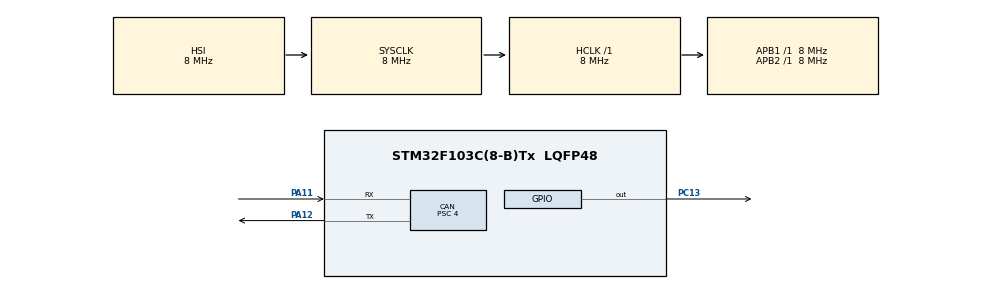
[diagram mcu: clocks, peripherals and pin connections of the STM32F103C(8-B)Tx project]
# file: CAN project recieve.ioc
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CAN.BS1=CAN_BS1_13TQ
CAN.BS2=CAN_BS2_2TQ
CAN.CalculateBaudRate=125000
CAN.CalculateTimeBit=8000
CAN.CalculateTimeQuantum=500.0
CAN.Prescaler=4
CAN.SJW=CAN_SJW_1TQ
Mcu.Family=STM32F1
Mcu.Name=STM32F103C(8-B)Tx
Mcu.Package=LQFP48
NVIC.PriorityGroup=NVIC_PRIORITYGROUP_4
NVIC.USB_LP_CAN1_RX0_IRQn=true\:0\:0\:false\:false\:true\:true\:true\:true
PA11.Mode=CAN_Activate
PA11.Signal=CAN_RX
PA12.Mode=CAN_Activate
PA12.Signal=CAN_TX
PC13-TAMPER-RTC.Signal=GPIO_Output
ProjectManager.HeapSize=0x200
ProjectManager.StackSize=0x400
ProjectManager.TargetToolchain=STM32CubeIDE
RCC.AHBFreq_Value=8000000
RCC.APB1Freq_Value=8000000
RCC.APB1TimFreq_Value=8000000
RCC.APB2Freq_Value=8000000
RCC.APB2TimFreq_Value=8000000
RCC.HCLKFreq_Value=8000000
RCC.SYSCLKFreq_VALUE=8000000
RCC.USBFreq_Value=8000000
VP_SYS_VS_ND.Mode=No_Debug
board=custom

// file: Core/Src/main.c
/* USER CODE BEGIN Header */
/**
  ******************************************************************************
  * @file           : main.c  (RECEIVER)
  * @brief          : Receives CAN frame ID 0x103, toggles LED on each frame
  ******************************************************************************
  */
/* USER CODE END Header */
#include "main.h"

CAN_HandleTypeDef hcan;

/* USER CODE BEGIN PV */
CAN_RxHeaderTypeDef   RxHeader;
uint8_t               RxData[3];
volatile uint8_t      datacheck = 0;
/* USER CODE END PV */

void SystemClock_Config(void);
static void MX_GPIO_Init(void);
static void MX_CAN_Init(void);

int main(void)
{

  /* MCU Configuration--------------------------------------------------------*/

  /* Reset of all peripherals, Initializes the Flash interface and the Systick. */
  HAL_Init();

  /* Configure the system clock */
  SystemClock_Config();

  /* Initialize all configured peripherals */
  MX_GPIO_Init();
  MX_CAN_Init();
  /* USER CODE BEGIN 2 */

  uint16_t acceptID = 0x002;
  /* At least one filter is required to receive. This one accepts all IDs. */
  CAN_FilterTypeDef canfilterconfig;
  canfilterconfig.FilterActivation     = CAN_FILTER_ENABLE;
  canfilterconfig.FilterBank           = 0;
  canfilterconfig.FilterFIFOAssignment = CAN_RX_FIFO0;
  canfilterconfig.FilterIdHigh         = acceptID << 5;		//the id that wil be accepted;
  canfilterconfig.FilterIdLow          = 0x0000;
  canfilterconfig.FilterMaskIdHigh     = 0x7FF << 5;		//compare the 11 bits;
  canfilterconfig.FilterMaskIdLow      = 0x0006;
  canfilterconfig.FilterMode           = CAN_FILTERMODE_IDMASK;
  canfilterconfig.FilterScale          = CAN_FILTERSCALE_32BIT;
  canfilterconfig.SlaveStartFilterBank = 14;

  if (HAL_CAN_ConfigFilter(&hcan, &canfilterconfig) != HAL_OK)
  {
    Error_Handler();
  }

  if (HAL_CAN_Start(&hcan) != HAL_OK)
  {
    Error_Handler();
  }

  /* Enables the interrupt inside the CAN peripheral.
     The NVIC line "CAN1 RX0 interrupt" must ALSO be enabled in CubeMX
     (CAN -> NVIC Settings) so CAN1_RX0_IRQHandler exists and calls HAL_CAN_IRQHandler. */
  if (HAL_CAN_ActivateNotification(&hcan, CAN_IT_RX_FIFO0_MSG_PENDING) != HAL_OK)
  {
    Error_Handler();
  }

  /* USER CODE END 2 */

  /* Infinite loop */
  /* USER CODE BEGIN WHILE */
  while (1)
  {
    if (datacheck)
    {
      datacheck = 0;
      HAL_GPIO_TogglePin(GPIOC, GPIO_PIN_13);
    }
    /* USER CODE END WHILE */

  }
}

void SystemClock_Config(void)
{
  RCC_OscInitTypeDef RCC_OscInitStruct = {0};
  RCC_ClkInitTypeDef RCC_ClkInitStruct = {0};

  /** Initializes the RCC Oscillators according to the specified parameters
  * in the RCC_OscInitTypeDef structure.
  */
  RCC_OscInitStruct.OscillatorType = RCC_OSCILLATORTYPE_HSI;
  RCC_OscInitStruct.HSIState = RCC_HSI_ON;
  RCC_OscInitStruct.HSICalibrationValue = RCC_HSICALIBRATION_DEFAULT;
  RCC_OscInitStruct.PLL.PLLState = RCC_PLL_NONE;
  if (HAL_RCC_OscConfig(&RCC_OscInitStruct) != HAL_OK)
  {
    Error_Handler();
  }

  /** Initializes the CPU, AHB and APB buses clocks
  */
  RCC_ClkInitStruct.ClockType = RCC_CLOCKTYPE_HCLK|RCC_CLOCKTYPE_SYSCLK
                              |RCC_CLOCKTYPE_PCLK1|RCC_CLOCKTYPE_PCLK2;
  RCC_ClkInitStruct.SYSCLKSource = RCC_SYSCLKSOURCE_HSI;
  RCC_ClkInitStruct.AHBCLKDivider = RCC_SYSCLK_DIV1;
  RCC_ClkInitStruct.APB1CLKDivider = RCC_HCLK_DIV1;
  RCC_ClkInitStruct.APB2CLKDivider = RCC_HCLK_DIV1;

  if (HAL_RCC_ClockConfig(&RCC_ClkInitStruct, FLASH_LATENCY_0) != HAL_OK)
  {
    Error_Handler();
  }
}

static void MX_CAN_Init(void)
{

  hcan.Instance = CAN1;
  hcan.Init.Prescaler = 4;
  hcan.Init.Mode = CAN_MODE_NORMAL;
  hcan.Init.SyncJumpWidth = CAN_SJW_1TQ;
  hcan.Init.TimeSeg1 = CAN_BS1_13TQ;
  hcan.Init.TimeSeg2 = CAN_BS2_2TQ;
  hcan.Init.TimeTriggeredMode = DISABLE;
  hcan.Init.AutoBusOff = DISABLE;
  hcan.Init.AutoWakeUp = DISABLE;
  hcan.Init.AutoRetransmission = DISABLE;
  hcan.Init.ReceiveFifoLocked = DISABLE;
  hcan.Init.TransmitFifoPriority = DISABLE;
  if (HAL_CAN_Init(&hcan) != HAL_OK)
  {
    Error_Handler();
  }

}

static void MX_GPIO_Init(void)
{
  GPIO_InitTypeDef GPIO_InitStruct = {0};

  /* GPIO Ports Clock Enable */
  __HAL_RCC_GPIOC_CLK_ENABLE();
  __HAL_RCC_GPIOA_CLK_ENABLE();

  /*Configure GPIO pin Output Level */
  HAL_GPIO_WritePin(GPIOC, GPIO_PIN_13, GPIO_PIN_RESET);

  /*Configure GPIO pin : PC13 */
  GPIO_InitStruct.Pin = GPIO_PIN_13;
  GPIO_InitStruct.Mode = GPIO_MODE_OUTPUT_PP;
  GPIO_InitStruct.Pull = GPIO_NOPULL;
  GPIO_InitStruct.Speed = GPIO_SPEED_FREQ_LOW;
  HAL_GPIO_Init(GPIOC, &GPIO_InitStruct);

}

/* USER CODE BEGIN 4 */
/* Called from the interrupt when a frame arrives in FIFO0.
   Parameter renamed so it does not shadow the global hcan. */
void HAL_CAN_RxFifo0MsgPendingCallback(CAN_HandleTypeDef *hcanp)
{
  if (HAL_CAN_GetRxMessage(hcanp, CAN_RX_FIFO0, &RxHeader, RxData) != HAL_OK)
  {
    Error_Handler();
  }
  //if (RxHeader.IDE == CAN_ID_STD && RxHeader.StdId == 0x001)

    datacheck = 1;

}
/* USER CODE END 4 */

void Error_Handler(void)
{
  __disable_irq();
  while (1)
  {
  }
}
